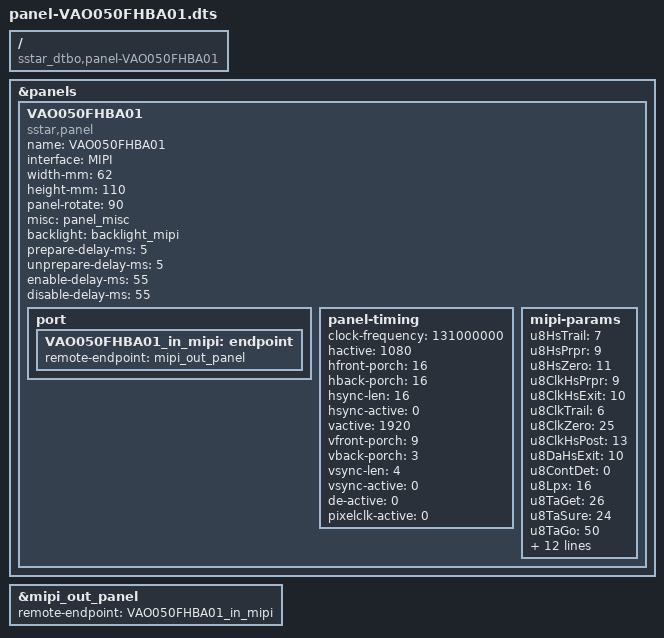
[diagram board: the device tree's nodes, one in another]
/dts-v1/;
/plugin/;

/ {
    compatible = "sstar_dtbo,panel-VAO050FHBA01";
};

&panels {

    VAO050FHBA01 {
        compatible = "sstar,panel";
        name = "VAO050FHBA01";
        interface = "MIPI";
        width-mm = <62>;
        height-mm = <110>;
        panel-rotate = <90>;
        misc = <&panel_misc>;
        backlight = <&backlight_mipi>;
        prepare-delay-ms = <5>;
        unprepare-delay-ms = <5>;
        enable-delay-ms = <55>;
        disable-delay-ms = <55>;
        status = "okay";

        port {
            VAO050FHBA01_in_mipi: endpoint {
                remote-endpoint = <&mipi_out_panel>;
            };
        };

        panel-timing {
            clock-frequency = <131000000>;
            hactive = <1080>;
            hfront-porch = <16>;
            hback-porch = <16>;
            hsync-len = <16>;
            hsync-active = <0>;
            vactive = <1920>;
            vfront-porch = <9>;
            vback-porch = <3>;
            vsync-len = <4>;
            vsync-active = <0>;
            de-active = <0>;
            pixelclk-active = <0>;
        };

        mipi-params {
            u8HsTrail = <7>;
            u8HsPrpr = <9>;
            u8HsZero = <11>;
            u8ClkHsPrpr = <9>;
            u8ClkHsExit = <10>;
            u8ClkTrail = <6>;
            u8ClkZero = <25>;
            u8ClkHsPost = <13>;
            u8DaHsExit = <10>;
            u8ContDet = <0>;
            u8Lpx = <16>;
            u8TaGet = <26>;
            u8TaSure = <24>;
            u8TaGo = <50>;

            u16Bllp = <0>;
            u16Fps = <60>;

            enFormat = <3>;
            enCtrl = <1>;

            u8SyncCalibrate = <0>;
            u16VirHsyncSt = <0>;
            u16VirHsyncEnd = <0>;
            u16VsyncRef = <0>;
            u16DataClkSkew = <7>;

            enPacketType = <0>;
            mipi-init-cmds = /bits/ 8 <
                0xB9 0x03 0xFF 0x83 0x99
                0xB1 0x0C 0x00 0x64 0x39 0x3B 0x44 0x09 0x22 0x22 0x71 0xF1 0x54 0x5E
                0xB2 0x0A 0x00 0x80 0x00 0x7F 0x0A 0x0E 0x30 0x4D 0x01 0x01
                0xB4 0x28 0x00 0xFF 0x02 0x40 0x02 0x40 0x00 0x00 0x06 0x00 0x01 0x02 0x00 0x0F 0x01 0x02 0x05 0x20 0x00 0x04 0x44 0x02 0x40 0x02 0x40 0x00 0x00 0x06 0x00 0x01 0x02 0x00 0x0F 0x01 0x02 0x05 0x00 0x00 0x04 0x44
                0xD3 0x1F 0x00 0x00 0x00 0x00 0x00 0x18 0x18 0x32 0x10 0x09 0x00 0x09 0x00 0x00 0x00 0x00 0x00 0x00 0x00 0x00 0x00 0x00 0x11 0x02 0x02 0x03 0x00 0x00 0x00 0x0A 0x08
                0xFE 0xFE 0x05
                0xD5 0x20 0x18 0x18 0x18 0x18 0x21 0x20 0x18 0x18 0x19 0x19 0x19 0x19 0x18 0x18 0x18 0x18 0x03 0x02 0x01 0x00 0x30 0x30 0x31 0x31 0x32 0x32 0x18 0x18 0x18 0x18 0x18 0x18
                0xFE 0xFE 0x05
                0xD6 0x20 0x18 0x18 0x18 0x18 0x20 0x21 0x19 0x19 0x18 0x18 0x19 0x19 0x18 0x18 0x18 0x18 0x00 0x01 0x02 0x03 0x30 0x30 0x31 0x31 0x32 0x32 0x18 0x18 0x18 0x18 0x18 0x18
                0xFE 0xFE 0x05
                0xD8 0x30 0x0A 0xBE 0xFA 0xA0 0x0A 0xBE 0xFA 0xA0 0x0A 0xBE 0xFA 0xA0 0x0A 0xBE 0xFA 0xA0 0x0F 0xFF 0xFF 0xE0 0x0F 0xFF 0xFF 0xE0 0x0F 0xFF 0xFF 0xE0 0x0F 0xFF 0xFF 0xE0 0x0F 0xFF 0xFF 0xE0 0x0F 0xFF 0xFF 0xE0 0x0F 0xFF 0xFF 0xE0 0x0F 0xFF 0xFF 0xE0
                0xE0 0x2A 0x00 0x02 0x06 0x2D 0x30 0x3F 0x14 0x39 0x06 0x0C 0x0F 0x11 0x13 0x11 0x12 0x11 0x17 0x0A 0x17 0x06 0x12 0x00 0x02 0x06 0x2D 0x30 0x3F 0x14 0x39 0x06 0x0C 0x0F 0x11 0x13 0x11 0x12 0x11 0x17 0x0A 0x17 0x06 0x12
                0xB6 0x02 0x14 0x14
                0xCC 0x01 0x08
                0xC0 0x02 0x01 0x91
                0x11 0x00 0x00
                0xFE 0xFE 0x78
                0x29 0x00 0x00
                0xFE 0xFE 0x14
                0xFF 0xFF
            >;
        };
    };
};

&mipi_out_panel {
    remote-endpoint = <&VAO050FHBA01_in_mipi>;
};
